# F28x7x_upp_regs register map
Vendor: Texas Instruments
Peripheral module from a debugger description file (folder C2000).
Address unit: 16 bits
Registers are 32-bit, read-write, no defined reset value unless marked. A register's access mark holds for its fields unless they carry their own. Offsets are as the file gives them; lines under a group give offsets from that group; [hi:lo] are bit positions; {n}, {i} and the like mark numbered series; 'fields as' and 'values as' point back to an identical list; <NAME> marks a mode.

## UPP_REGS — UPP Registers
0x00 PID ro — Peripheral ID Register
  [31:0] REVID — Module revision id.
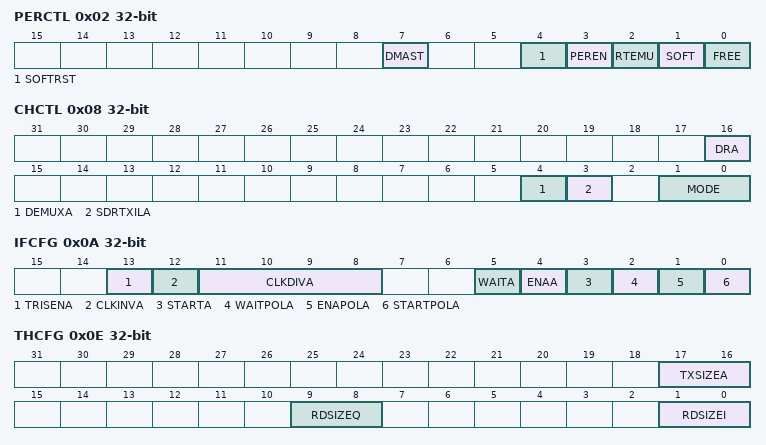
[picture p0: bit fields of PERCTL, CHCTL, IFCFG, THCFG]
0x02 PERCTL access per field — Peripheral Control Register
  [7] DMAST ro — DMA Burst transaction status
  [4] SOFTRST rw — Software Reset
  [3] PEREN rw — Peripheral Enable
  [2] RTEMU rw — Realtime emulation control.
  [1] SOFT rw — Emulation control.
  [0] FREE rw — Emulation control.
0x08 CHCTL — General Control Register
  [16] DRA — Data rate
  [4] DEMUXA — DDR de-multiplexing mode
  [3] SDRTXILA — SDR TX Interleve mode
  [1:0] MODE — Operating mode
0x0A IFCFG — Interface Configuration Register
  [13] TRISENA — Pin Tri-state Control
  [12] CLKINVA — Clock inversion
  [11:8] CLKDIVA — Clock divider for tx mode
  [5] WAITA — Enable Usage of WAIT signal
  [4] ENAA — Enable Usage of ENABLE (WRITE) signal
  [3] STARTA — Enable Usage of START (SELECT) signal
  [2] WAITPOLA — Polarity of WAIT signal.
  [1] ENAPOLA — Polarity of ENABLE(WRITE) signal
  [0] STARTPOLA — Polarity of START(SELECT) signal
0x0C IFIVAL — Interface Idle Value Register
  [8:0] VALA — Idle Value
0x0E THCFG — Threshold Configuration Register
  [17:16] TXSIZEA — I/O Transmit Threshold Value
  [9:8] RDSIZEQ — DMA Read Threshold for DMA Channel Q
  [1:0] RDSIZEI — DMA Read Threshold for DMA Channel I
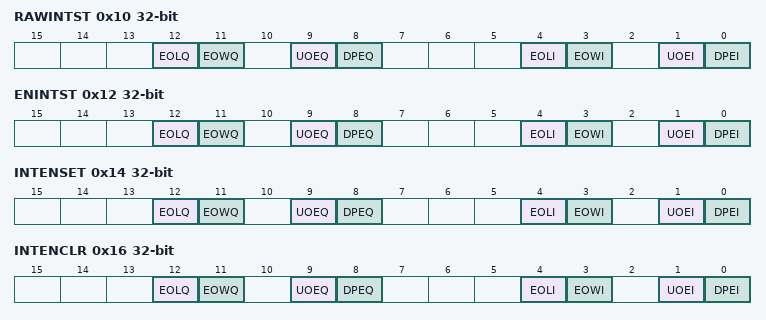
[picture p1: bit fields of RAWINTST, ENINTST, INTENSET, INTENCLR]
0x10 RAWINTST — Raw Interrupt Status Register
  [12] EOLQ — Interrupt raw status for end-of-line condition
  [11] EOWQ — Interrupt raw status for end-of window condition
  [9] UOEQ — Interrupt raw status for DMA under-run or over-run
  [8] DPEQ — Interrupt raw status for DMA programming error
  [4] EOLI — Interrupt raw status for end-of-line condition
  [3] EOWI — Interrupt raw status for end-of window condition
  [1] UOEI — Interrupt raw status for DMA under-run or over-run
  [0] DPEI — Interrupt raw status for DMA programming error
0x12 ENINTST access not given — Enable Interrupt Status Register
  [12] EOLQ — Interrupt enable status for end-of-line condition (access R/W1toClr)
  [11] EOWQ — Interrupt enable status for end-of window condition (access R/W1toClr)
  [9] UOEQ — Interrupt enable status for DMA under-run or over-run (access R/W1toClr)
  [8] DPEQ — Interrupt enable status for DMA programming error (access R/W1toClr)
  [4] EOLI — Interrupt enable status for end-of-line condition (access R/W1toClr)
  [3] EOWI — Interrupt enable status for end-of window condition (access R/W1toClr)
  [1] UOEI — Interrupt enable status for DMA under-run or over-run (access R/W1toClr)
  [0] DPEI — Interrupt enable status for DMA programming error (access R/W1toClr)
0x14 INTENSET — Interrupt Enable Set Register
  [12] EOLQ — Interrupt enable for end-of-line condition
  [11] EOWQ — Interrupt enable for end-of window condition
  [9] UOEQ — Interrupt enable for DMA under-run or over-run
  [8] DPEQ — Interrupt enable for DMA programming error
  [4] EOLI — Interrupt enable for end-of-line condition
  [3] EOWI — Interrupt enable for end-of window condition
  [1] UOEI — Interrupt enable for DMA under-run or over-run
  [0] DPEI — Interrupt enable for DMA programming error
0x16 INTENCLR — Interrupt Enable Clear Register
  [12] EOLQ — Interrupt clear for end-of-line condition
  [11] EOWQ — Interrupt clear for end-of window condition
  [9] UOEQ — Interrupt clear for DMA under-run or over-run
  [8] DPEQ — Interrupt clear for DMA programming error
  [4] EOLI — Interrupt clear for end-of-line condition
  [3] EOWI — Interrupt clear for end-of window condition
  [1] UOEI — Interrupt clear for DMA under-run or over-run
  [0] DPEI — Interrupt clear for DMA programming error
0x20 CHIDESC0 — DMA Channel I Descriptor 0 Register
  [31:0] ADDR — Starting address of the DMA Channel I transfer.
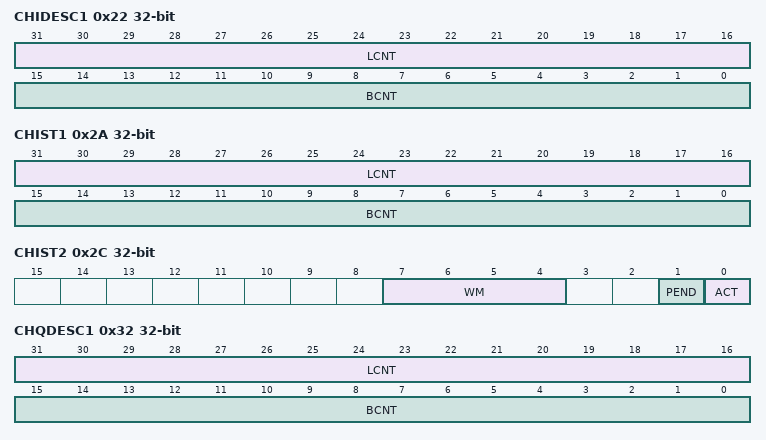
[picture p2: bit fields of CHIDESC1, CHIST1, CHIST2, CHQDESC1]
0x22 CHIDESC1 — DMA Channel I Descriptor 1 Register
  [31:16] LCNT — Number of lines in a window for DMA Channel I transfer.
  [15:0] BCNT — Number of bytes in a line for DMA Channel I transfer.
0x24 CHIDESC2 — DMA Channel I Descriptor 2 Register
  [15:0] LOFFSET — Current start address to next start address offset.
0x28 CHIST0 ro — DMA Channel I Status 0 Register
  [31:0] ADDR — Current address of the DMA transfer.
0x2A CHIST1 ro — DMA Channel I Status 1 Register
  [31:16] LCNT — Current line number.
  [15:0] BCNT — Current byte number.
0x2C CHIST2 ro — DMA Channel I Status 2 Register
  [7:4] WM — Watermark for FIFO block count for DMA Channel I tranfer.
  [1] PEND — Status of DMA.
  [0] ACT — Status of DMA descriptor.
0x30 CHQDESC0 — DMA Channel Q Descriptor 0 Register
  [31:0] ADDR — Starting address of the DMA Channel Q transfer.
0x32 CHQDESC1 — DMA Channel Q Descriptor 1 Register
  [31:16] LCNT — Number of lines in a window for DMA Channel Q transfer.
  [15:0] BCNT — Number of bytes in a line for DMA Channel Q transfer.
0x34 CHQDESC2 — DMA Channel Q Descriptor 2 Register
  [15:0] LOFFSET — Current start address to next start address offset.
0x38 CHQST0 ro — DMA Channel Q Status 0 Register
  [31:0] ADDR — Current address of the DMA transfer.
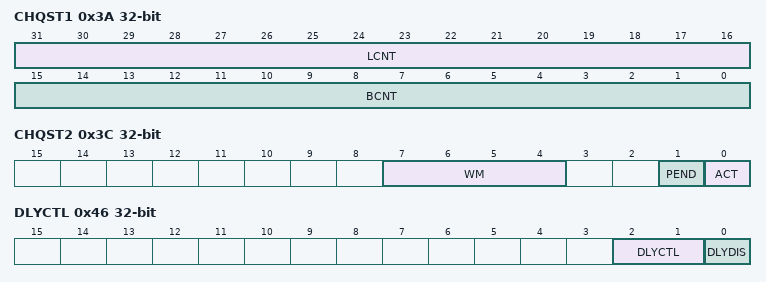
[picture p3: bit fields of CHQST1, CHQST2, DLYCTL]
0x3A CHQST1 ro — DMA Channel Q Status 1 Register
  fields as CHIST1
0x3C CHQST2 ro — DMA Channel Q Status 2 Register
  [7:4] WM — Watermark for FIFO block count for DMA Channel Q tranfer.
  [1] PEND — Status of DMA.
  [0] ACT — Status of DMA descriptor.
0x40 GINTEN — Global Peripheral Interrupt Enable Register
  [0] GINTEN — Global Interrupt Enable
0x42 GINTFLG ro — Global Peripheral Interrupt Flag Register
  [0] GINTFLG — Global Interrupt Flag
0x44 GINTCLR access not given — Global Peripheral Interrupt Clear Register
  [0] GINTCLR — Global Interrupt Clear (access R=0/W=1)
0x46 DLYCTL — IO clock data skew control Register
  [2:1] DLYCTL — IO delay control.
  [0] DLYDIS — IO dealy control disable.
